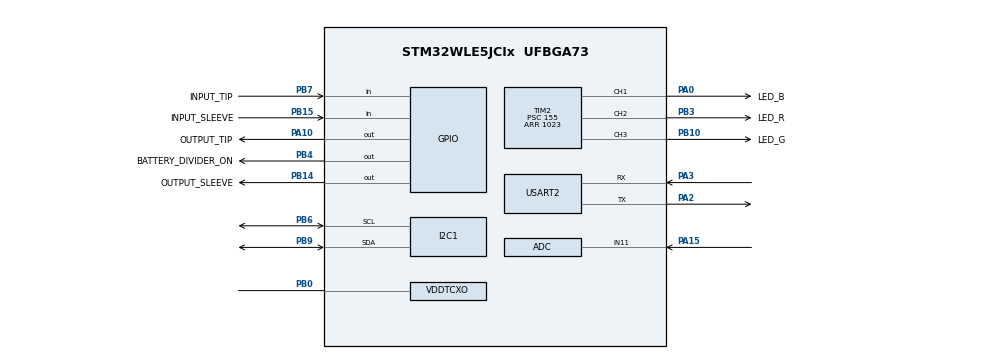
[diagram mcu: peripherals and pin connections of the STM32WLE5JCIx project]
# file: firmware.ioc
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ADC.Channel-0\#ChannelRegularConversion=ADC_CHANNEL_11
ADC.ClockPrescaler=ADC_CLOCK_SYNC_PCLK_DIV4
ADC.EnableRegularConversion=ENABLE
ADC.NbrOfConversion=1
ADC.NbrOfConversionFlag=1
ADC.Rank-0\#ChannelRegularConversion=1
ADC.SamplingTime-0\#ChannelRegularConversion=ADC_SAMPLINGTIME_COMMON_1
ADC.SamplingTimeCommon1=ADC_SAMPLETIME_160CYCLES_5
ADC.SamplingTimeCommon2=ADC_SAMPLETIME_160CYCLES_5
ADC.SelectedChannel=ADC_CHANNEL_11
Dma.Request0=USART2_TX
Dma.USART2_TX.0.Direction=DMA_MEMORY_TO_PERIPH
Dma.USART2_TX.0.EventEnable=DISABLE
Dma.USART2_TX.0.Instance=DMA1_Channel1
Dma.USART2_TX.0.MemDataAlignment=DMA_MDATAALIGN_BYTE
Dma.USART2_TX.0.MemInc=DMA_MINC_ENABLE
Dma.USART2_TX.0.Mode=DMA_NORMAL
Dma.USART2_TX.0.PeriphDataAlignment=DMA_PDATAALIGN_BYTE
Dma.USART2_TX.0.PeriphInc=DMA_PINC_DISABLE
Dma.USART2_TX.0.Polarity=HAL_DMAMUX_REQ_GEN_RISING
Dma.USART2_TX.0.Priority=DMA_PRIORITY_LOW
Dma.USART2_TX.0.RequestNumber=1
Dma.USART2_TX.0.SignalID=NONE
Dma.USART2_TX.0.SyncEnable=DISABLE
Dma.USART2_TX.0.SyncPolarity=HAL_DMAMUX_SYNC_NO_EVENT
Dma.USART2_TX.0.SyncRequestNumber=1
Dma.USART2_TX.0.SyncSignalID=NONE
I2C1.Timing=0x10805D88
Mcu.Family=STM32WL
Mcu.Name=STM32WLE5JCIx
Mcu.Package=UFBGA73
Mcu.UserConstants=RTC_N_PREDIV_S,10;RTC_PREDIV_S,((1<<RTC_N_PREDIV_S)-1);RTC_PREDIV_A,((1<<(15-RTC_N_PREDIV_S))-1)
NVIC.ADC_IRQn=true\:0\:0\:false\:false\:true\:true\:true\:true
NVIC.DMA1_Channel1_IRQn=true\:0\:0\:false\:false\:true\:false\:true\:true
NVIC.PriorityGroup=NVIC_PRIORITYGROUP_4
NVIC.SUBGHZ_Radio_IRQn=true\:0\:0\:false\:false\:true\:true\:true\:true
NVIC.TIM17_IRQn=true\:0\:0\:false\:false\:true\:true\:true\:true
NVIC.USART2_IRQn=true\:0\:0\:false\:false\:true\:true\:true\:true
OSC_IN.Mode=HSE-TCXO
OSC_IN.Signal=RCC_OSC_IN
PA0.GPIO_Label=LED_B
PA0.Signal=S_TIM2_CH1
PA10.GPIO_Label=OUTPUT_TIP
PA10.GPIO_PuPd=GPIO_PULLUP
PA10.PinState=GPIO_PIN_SET
PA10.Signal=GPIO_Output
PA13.Mode=Serial_Wire
PA13.Signal=DEBUG_JTMS-SWDIO
PA14.Mode=Serial_Wire
PA14.Signal=DEBUG_JTCK-SWCLK
PA15.Mode=IN11
PA15.Signal=ADC_IN11
PA2.Mode=Asynchronous
PA2.Signal=USART2_TX
PA3.Mode=Asynchronous
PA3.Signal=USART2_RX
PB0-VDD_TCXO.Mode=HSE-TCXO
PB0-VDD_TCXO.Signal=VDDTCXO
PB10.GPIO_Label=LED_G
PB10.Signal=S_TIM2_CH3
PB14.GPIO_Label=OUTPUT_SLEEVE
PB14.PinState=GPIO_PIN_SET
PB14.Signal=GPIO_Output
PB15.GPIO_Label=INPUT_SLEEVE
PB15.GPIO_PuPd=GPIO_PULLUP
PB15.Signal=GPIO_Input
PB3.GPIO_Label=LED_R
PB3.Signal=S_TIM2_CH2
PB4.GPIO_Label=BATTERY_DIVIDER_ON
PB4.Signal=GPIO_Output
PB6.Mode=I2C
PB6.Signal=I2C1_SCL
PB7.GPIO_Label=INPUT_TIP
PB7.GPIO_PuPd=GPIO_PULLUP
PB7.Signal=GPIO_Input
PB9.Mode=I2C
PB9.Signal=I2C1_SDA
PC14-OSC32_IN.Mode=LSE-External-Oscillator
PC14-OSC32_IN.Signal=RCC_OSC32_IN
PC15-OSC32_OUT.Mode=LSE-External-Oscillator
PC15-OSC32_OUT.Signal=RCC_OSC32_OUT
ProjectManager.HeapSize=0x200
ProjectManager.StackSize=0x400
ProjectManager.TargetToolchain=Makefile
RCC.AHBFreq_Value=48000000
RCC.APB1Freq_Value=48000000
RCC.APB1TimFreq_Value=48000000
RCC.APB2Freq_Value=48000000
RCC.APB2TimFreq_Value=48000000
RCC.APB3Freq_Value=48000000
RCC.CortexFreq_Value=48000000
RCC.HCLKFreq_Value=48000000
RCC.HSE_VALUE=8000000
RCC.HSI_VALUE=16000000
RCC.LSE_VALUE=32768
RCC.MSIClockRange=RCC_MSIRANGE_11
RCC.PLLSourceVirtual=RCC_PLLSOURCE_HSI
RCC.SYSCLKFreq_VALUE=48000000
RCC.VCOOutputFreq_Value=128000000
SH.S_TIM2_CH1.0=TIM2_CH1,PWM Generation1 CH1
SH.S_TIM2_CH2.0=TIM2_CH2,PWM Generation2 CH2
SH.S_TIM2_CH3.0=TIM2_CH3,PWM Generation3 CH3
SUBGHZ.BaudratePrescaler=SUBGHZSPI_BAUDRATEPRESCALER_4
TIM17.Period=9
TIM17.Prescaler=47999
TIM2.Channel-PWM\ Generation1\ CH1=TIM_CHANNEL_1
TIM2.Channel-PWM\ Generation2\ CH2=TIM_CHANNEL_2
TIM2.Channel-PWM\ Generation3\ CH3=TIM_CHANNEL_3
TIM2.OCPolarity_1=TIM_OCPOLARITY_LOW
TIM2.OCPolarity_2=TIM_OCPOLARITY_LOW
TIM2.OCPolarity_3=TIM_OCPOLARITY_LOW
TIM2.Period=1023
TIM2.Prescaler=155
TIM2.Pulse-PWM\ Generation1\ CH1=499
TIM2.Pulse-PWM\ Generation2\ CH2=499
TIM2.Pulse-PWM\ Generation3\ CH3=499
USART2.VirtualMode-Asynchronous=VM_ASYNC
VP_SUBGHZ_VS_SUBGHZ.Mode=SUBGHZ_Activate
VP_TIM17_VS_ClockSourceINT.Mode=Enable_Timer
VP_TIM2_VS_ClockSourceINT.Mode=Internal
board=custom

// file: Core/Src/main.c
/* USER CODE BEGIN Header */
/**
 ******************************************************************************
 * @file           : main.c
 * @brief          : Main program body
 ******************************************************************************
 * @attention
 *
 * <h2><center>&copy; Copyright (c) 2021 STMicroelectronics.
 * All rights reserved.</center></h2>
 *
 * This software component is licensed by ST under BSD 3-Clause license,
 * the "License"; You may not use this file except in compliance with the
 * License. You may obtain a copy of the License at:
 *                        opensource.org/licenses/BSD-3-Clause
 *
 ******************************************************************************
 */
/* USER CODE END Header */
#include "main.h"
#include "adc.h"
#include "dma.h"
#include "i2c.h"
#include "tim.h"
#include "usart.h"
#include "gpio.h"

/* USER CODE BEGIN Includes */
#include "app.h"
#include "bootloader.h"
/* USER CODE END Includes */

void SystemClock_Config(void);

int main(void)
{

  /* USER CODE BEGIN 1 */

  // Pre-init:
  // Check if entering the bootloader was requested
  // before reset
  bootloader_check();

  /* USER CODE END 1 */

  /* MCU Configuration--------------------------------------------------------*/

  /* Reset of all peripherals, Initializes the Flash interface and the Systick. */
  HAL_Init();

  /* Configure the system clock */
  SystemClock_Config();

  /* Initialize all configured peripherals */
  MX_GPIO_Init();
  MX_DMA_Init();
  MX_TIM2_Init();
  MX_ADC_Init();
  MX_USART2_UART_Init();
  MX_TIM17_Init();
  MX_I2C1_Init();
  /* USER CODE BEGIN 2 */

  app_init();

  // volatile flash_backup_t *foo = flash_backup_read();

  // uint32_t len = 0;
  // uint8_t buffer[8];
  // uint32_t last_tick = HAL_GetTick();
  /* USER CODE END 2 */

  /* Infinite loop */
  /* USER CODE BEGIN WHILE */
  while (1)
  {

    app_main_loop();
    /* USER CODE END WHILE */

  }
}

void SystemClock_Config(void)
{
  RCC_OscInitTypeDef RCC_OscInitStruct = {0};
  RCC_ClkInitTypeDef RCC_ClkInitStruct = {0};

  /** Configure LSE Drive Capability
   */
  HAL_PWR_EnableBkUpAccess();
  __HAL_RCC_LSEDRIVE_CONFIG(RCC_LSEDRIVE_LOW);

  /** Configure the main internal regulator output voltage
   */
  __HAL_PWR_VOLTAGESCALING_CONFIG(PWR_REGULATOR_VOLTAGE_SCALE1);

  /** Initializes the CPU, AHB and APB buses clocks
   */
  RCC_OscInitStruct.OscillatorType = RCC_OSCILLATORTYPE_LSE | RCC_OSCILLATORTYPE_MSI;
  RCC_OscInitStruct.LSEState = RCC_LSE_ON;
  RCC_OscInitStruct.MSIState = RCC_MSI_ON;
  RCC_OscInitStruct.MSICalibrationValue = RCC_MSICALIBRATION_DEFAULT;
  RCC_OscInitStruct.MSIClockRange = RCC_MSIRANGE_11;
  RCC_OscInitStruct.PLL.PLLState = RCC_PLL_NONE;
  if (HAL_RCC_OscConfig(&RCC_OscInitStruct) != HAL_OK)
  {
    Error_Handler();
  }

  /** Configure the SYSCLKSource, HCLK, PCLK1 and PCLK2 clocks dividers
   */
  RCC_ClkInitStruct.ClockType = RCC_CLOCKTYPE_HCLK3 | RCC_CLOCKTYPE_HCLK | RCC_CLOCKTYPE_SYSCLK | RCC_CLOCKTYPE_PCLK1 | RCC_CLOCKTYPE_PCLK2;
  RCC_ClkInitStruct.SYSCLKSource = RCC_SYSCLKSOURCE_MSI;
  RCC_ClkInitStruct.AHBCLKDivider = RCC_SYSCLK_DIV1;
  RCC_ClkInitStruct.APB1CLKDivider = RCC_HCLK_DIV1;
  RCC_ClkInitStruct.APB2CLKDivider = RCC_HCLK_DIV1;
  RCC_ClkInitStruct.AHBCLK3Divider = RCC_SYSCLK_DIV1;

  if (HAL_RCC_ClockConfig(&RCC_ClkInitStruct, FLASH_LATENCY_2) != HAL_OK)
  {
    Error_Handler();
  }
}

void Error_Handler(void)
{
  __disable_irq();
  while (1)
  {
  }
}
